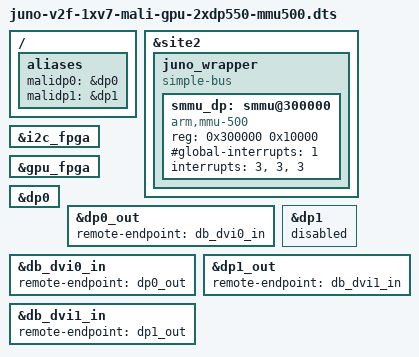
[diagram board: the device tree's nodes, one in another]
/*
 * ARM Juno development platform with single Virtex 7 logic tile
 * and HDMI daughterboard.
 * Configured for a bitfile containing a Mali GPU, dual-display DP550 and
 * corresponding MMU-500 shared between the DPs
 */

#include "juno.dts"

/ {
	aliases {
		malidp0 = &dp0;
		malidp1 = &dp1;
	};
};

&site2 {
	juno_wrapper {
		compatible = "simple-bus";
		#address-cells = <1>;
		#size-cells = <1>;
		/*
		 * The mapping on Juno is rather complicated.
		 * The lowest slaves: 0-0x0009ffff are mapped to 0x6f100000 (physical)
		 * The "mid" slaves:  0x00200000-0x004fffff are mapped to 0x6f200000 (physical)
		 * The "high" slaves: 0x0c000000-0x0c09ffff are mapped to 0x6f000000 (physical)
		 */
		ranges = <0          0x0f100000 0x0a0000>,
			 <0x00200000 0x0f200000 0x300000>,
			 <0x0c000000 0x0f000000 0x0a0000>;

		/include/ "v2f-1xv7-malidp-framework.dtsi"
		/include/ "v2f-1xv7-malidp-dp550.dtsi"

		/* The MMU-500 is used (with two TBUs) for some DP550 bitfiles */
		smmu_dp: smmu@300000 {
			compatible = "arm,mmu-500";
			reg = <0x300000 0x10000>;
			#global-interrupts = <1>;
			interrupts = <3>, <3>, <3>;
			#iommu-cells = <1>;
			status = "okay";
		};
	};
};

&i2c_fpga {
	status = "okay";
	/include/ "v2c-hdmi.dtsi"
};

&gpu_fpga {
	status = "okay";
};

/* Configure DP0 with daughterboard transmitter */
&dp0 {
	status = "okay";
};

&dp0_out {
	remote-endpoint = <&db_dvi0_in>;
};

&db_dvi0_in {
	remote-endpoint = <&dp0_out>;
};

/* Configure DP1 with daughterboard transmitter */
&dp1 {
	status = "disabled";
};

&dp1_out {
	remote-endpoint = <&db_dvi1_in>;
};

&db_dvi1_in {
	remote-endpoint = <&dp1_out>;
};

/* Enable the single MMU-500 for both DPs */
&smmu_dp {
	status = "okay";
};
